# N32G401 register map
Vendor: Nationstech Ltd.; File version: 1.0
Registers are 32-bit, read-write, reset 0x0 unless marked. A register's access mark holds for its fields unless they carry their own. Offsets are from the block's base; [hi:lo] are bit positions; {n}, {i} and the like mark numbered series; 'fields as' and 'values as' point back to an identical list.

## COMP — comparator
Base 0x40002400
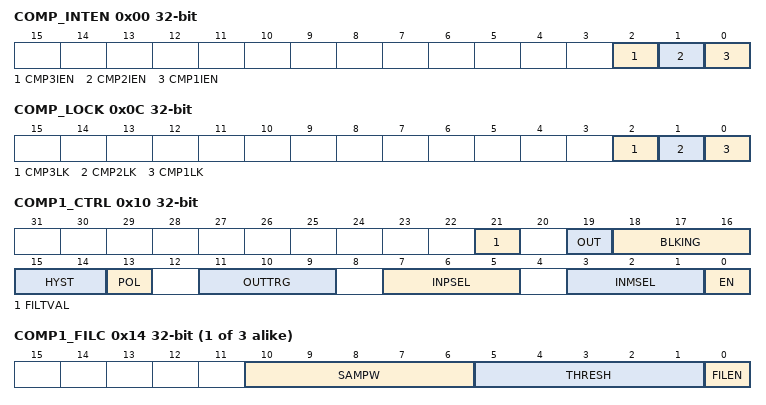
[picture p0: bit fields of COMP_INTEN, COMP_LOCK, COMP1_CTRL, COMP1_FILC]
0x00 COMP_INTEN
  [2] CMP3IEN, [1] CMP2IEN, [0] CMP1IEN
0x08 COMP_WINMODE
  [0] CMP12MD
0x0C COMP_LOCK
  [2] CMP3LK, [1] CMP2LK, [0] CMP1LK
0x10 COMP1_CTRL
  [21] FILTVAL, [19] OUT, [18:16] BLKING, [15:14] HYST, [13] POL, [11:9] OUTTRG, [7:5] INPSEL, [3:1] INMSEL, [0] EN
{0x4+0x10*i} COMP{i}_FILC (i=1..3)
  [10:6] SAMPW, [5:1] THRESH, [0] FILEN
{0x8+0x10*i} COMP{i}_FILP (i=1..3)
  [15:0] CLKPSC
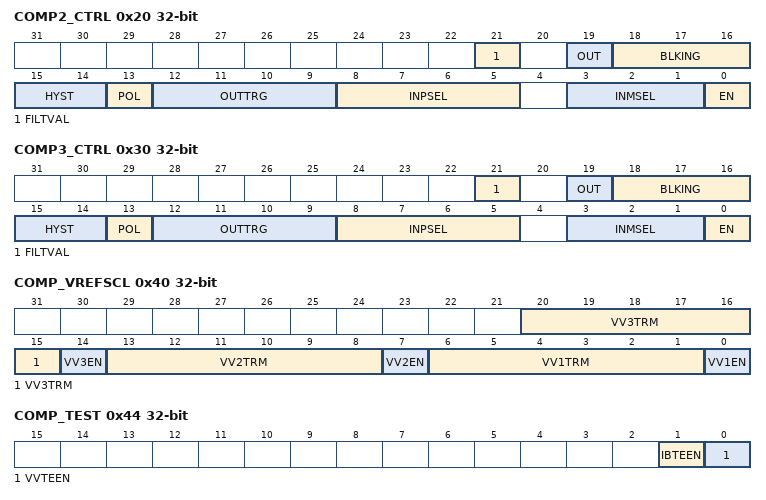
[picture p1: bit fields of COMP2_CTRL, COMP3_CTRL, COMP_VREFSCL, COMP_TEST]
0x20 COMP2_CTRL (reset mask 0xFFFEF)
  [21] FILTVAL, [19] OUT, [18:16] BLKING, [15:14] HYST, [13] POL, [12:9] OUTTRG, [8:5] INPSEL, [3:1] INMSEL, [0] EN
0x2C COMP2_OSEL
  [0] CMP2XO
0x30 COMP3_CTRL (reset mask 0xFFFEF)
  fields as COMP2_CTRL
0x40 COMP_VREFSCL
  [20:15] VV3TRM, [14] VV3EN, [13:8] VV2TRM, [7] VV2EN, [6:1] VV1TRM, [0] VV1EN
0x44 COMP_TEST
  [1] IBTEEN, [0] VVTEEN
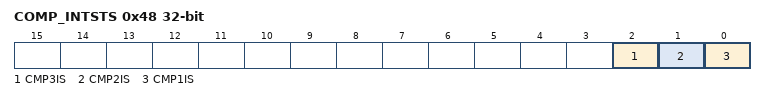
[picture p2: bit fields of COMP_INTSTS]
0x48 COMP_INTSTS
  [2] CMP3IS, [1] CMP2IS, [0] CMP1IS

## CRC — cyclic redundancy check
Base 0x40023000
0x00 CRC32DAT reset 0xFFFFFFFF
0x04 CRC32IDAT
  [7:0] CRC32IDAT
0x08 CRC32CTRL
  [0] RESET
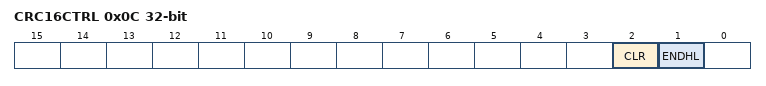
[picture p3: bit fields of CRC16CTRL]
0x0C CRC16CTRL
  [2] CLR, [1] ENDHL
0x10 CRC16DAT
  [7:0] CRC16DAT
0x14 CRC16D
  [15:0] CRC16D
0x18 LRC
  [7:0] LRCDAT

## DBG — debug support for MCU
Base 0xE0042000
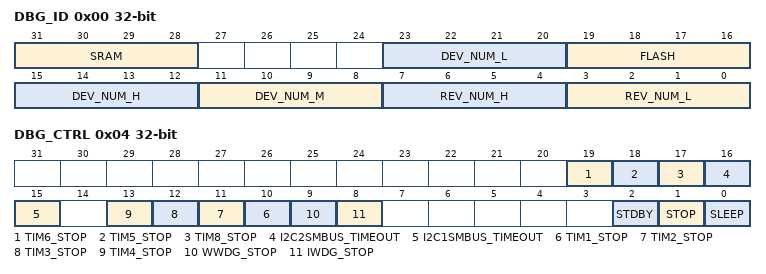
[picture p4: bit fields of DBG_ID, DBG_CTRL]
0x00 DBG_ID
  [31:28] SRAM, [23:20] DEV_NUM_L, [19:16] FLASH, [15:12] DEV_NUM_H, [11:8] DEV_NUM_M, [7:4] REV_NUM_H, [3:0] REV_NUM_L
0x04 DBG_CTRL
  [19] TIM6_STOP, [18] TIM5_STOP, [17] TIM8_STOP, [16] I2C2SMBUS_TIMEOUT, [15] I2C1SMBUS_TIMEOUT, [n+9] TIM{n}_STOP (n=1..4), [9] WWDG_STOP, [8] IWDG_STOP, [2] STDBY, [1] STOP, [0] SLEEP

## DMA — Direct memory access controller
Base 0x40020000
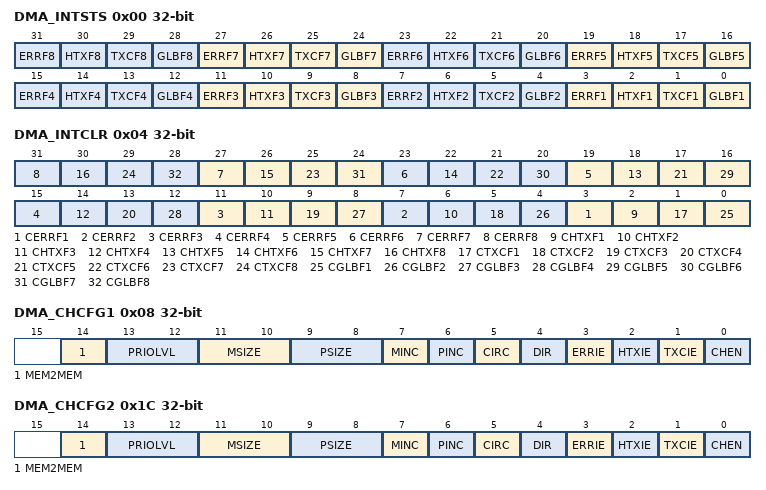
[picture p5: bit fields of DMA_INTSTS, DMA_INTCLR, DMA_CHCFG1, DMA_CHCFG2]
0x00 DMA_INTSTS
  [4n-1] ERRF{n} (n=1..8), [4n-2] HTXF{n} (n=1..8), [4n-3] TXCF{n} (n=1..8), [4n-4] GLBF{n} (n=1..8)
0x04 DMA_INTCLR
  [4n-1] CERRF{n} (n=1..8), [4n-2] CHTXF{n} (n=1..8), [4n-3] CTXCF{n} (n=1..8), [4n-4] CGLBF{n} (n=1..8)
0x08 DMA_CHCFG1
  [14] MEM2MEM, [13:12] PRIOLVL, [11:10] MSIZE, [9:8] PSIZE, [7] MINC, [6] PINC, [5] CIRC, [4] DIR, [3] ERRIE, [2] HTXIE, [1] TXCIE, [0] CHEN
0x0C DMA_TXNUM1
  [15:0] NDTX
0x10 DMA_PADDR1
  [31:0] ADDR
{0x0+0x14*i} DMA_MADDR{i} (i=1..8)
  [31:0] ADDR
{0x4+0x14*i} DMA_CHSEL{i} (i=1..8)
  [5:0] CH_SEL
0x1C DMA_CHCFG2
  fields as DMA_CHCFG1
0x20 DMA_TXNUM2
  [15:0] NDTX
0x24 DMA_PADDR2
  [31:0] ADDR
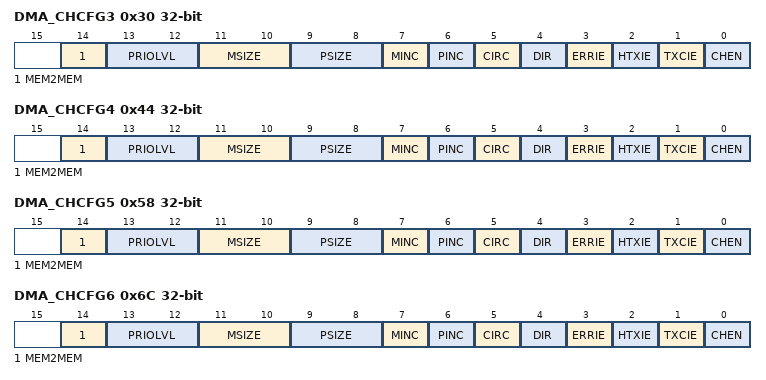
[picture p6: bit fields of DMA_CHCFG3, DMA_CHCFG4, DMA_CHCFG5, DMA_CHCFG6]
0x30 DMA_CHCFG3
  fields as DMA_CHCFG1
0x34 DMA_TXNUM3
  [15:0] NDTX
0x38 DMA_PADDR3
  [31:0] ADDR
0x44 DMA_CHCFG4
  fields as DMA_CHCFG1
0x48 DMA_TXNUM4
  [15:0] NDTX
0x4C DMA_PADDR4
  [31:0] ADDR
0x58 DMA_CHCFG5
  fields as DMA_CHCFG1
0x5C DMA_TXNUM5
  [15:0] NDTX
0x60 DMA_PADDR5
  [31:0] ADDR
0x6C DMA_CHCFG6
  fields as DMA_CHCFG1
0x70 DMA_TXNUM6
  [15:0] NDTX
0x74 DMA_PADDR6
  [31:0] ADDR
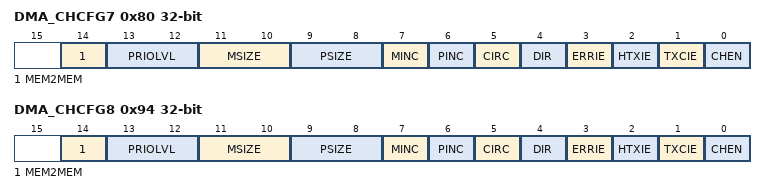
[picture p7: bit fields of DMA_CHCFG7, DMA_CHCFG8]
0x80 DMA_CHCFG7
  fields as DMA_CHCFG1
0x84 DMA_TXNUM7
  [15:0] NDTX
0x88 DMA_PADDR7
  [31:0] ADDR
0x94 DMA_CHCFG8
  fields as DMA_CHCFG1
0x98 DMA_TXNUM8
  [15:0] NDTX
0x9C DMA_PADDR8
  [31:0] ADDR

## EXTI — external interrupt/event controller
Base 0x40010400
0x00 EXTI_IMASK
  [23:0] IMASK
0x04 EXTI_EMASK
  [23:0] EMASK
0x08 EXTI_RT_CFG
  [23:0] RT_CFG
0x0C EXTI_FT_CFG
  [23:0] FT_CFG
0x10 EXTI_SWIE
  [23:0] SWIE
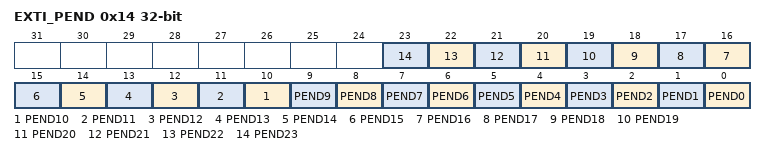
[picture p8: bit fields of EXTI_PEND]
0x14 EXTI_PEND
  [n] PEND{n} (n=0..23)
0x18 EXTI_TS_SEL
  [3:0] TSSEL

## FLASH — interal FLASH controller
Base 0x40022000
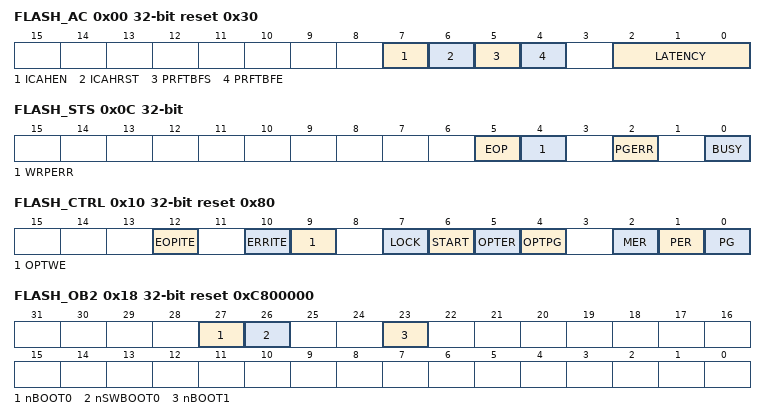
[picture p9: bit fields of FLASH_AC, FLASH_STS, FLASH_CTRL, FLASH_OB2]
0x00 FLASH_AC reset 0x30
  [7] ICAHEN, [6] ICAHRST, [5] PRFTBFS, [4] PRFTBFE, [2:0] LATENCY
0x04 FLASH_KEY
  [31:0] FKEY
0x08 FLASH_OPTKEY
0x0C FLASH_STS
  [5] EOP, [4] WRPERR, [2] PGERR, [0] BUSY
0x10 FLASH_CTRL reset 0x80
  [12] EOPITE, [10] ERRITE, [9] OPTWE, [7] LOCK, [6] START, [5] OPTER, [4] OPTPG, [2] MER, [1] PER, [0] PG
0x14 FLASH_ADD
  [31:0] FADD
0x18 FLASH_OB2 reset 0xC800000
  [27] nBOOT0, [26] nSWBOOT0, [23] nBOOT1
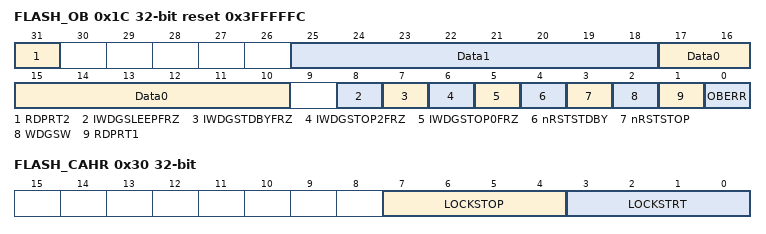
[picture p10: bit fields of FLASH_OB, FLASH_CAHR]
0x1C FLASH_OB reset 0x3FFFFFC
  [31] RDPRT2, [25:18] Data1, [17:10] Data0, [8] IWDGSLEEPFRZ, [7] IWDGSTDBYFRZ, [6] IWDGSTOP2FRZ, [5] IWDGSTOP0FRZ, [4] nRSTSTDBY, [3] nRSTSTOP, [2] WDGSW, [1] RDPRT1, [0] OBERR
0x20 FLASH_WRP reset 0xFFFF
  [15:0] WRPT
0x30 FLASH_CAHR
  [7:4] LOCKSTOP, [3:0] LOCKSTRT
